# DA14682 register map
Vendor: Dialog; Series: DA14682; File version: 1.2
CPU: CM0 r1p0, little endian, MPU, FPU, 3 interrupt priority bits
Registers are 16-bit, read-write, reset 0x0 unless marked. A register's access mark holds for its fields unless they carry their own. Offsets are from the block's base; [hi:lo] are bit positions; <NAME> marks a mode.

## ANAMISC — ANAMISC registers
Base 0x50001B00
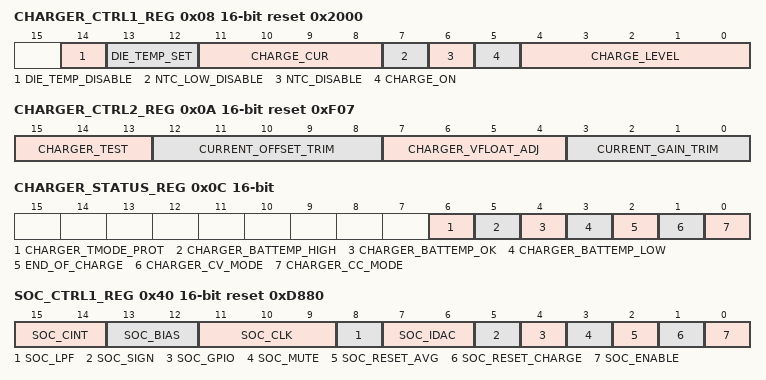
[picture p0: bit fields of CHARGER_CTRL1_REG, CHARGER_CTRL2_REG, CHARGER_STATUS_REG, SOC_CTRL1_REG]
0x08 CHARGER_CTRL1_REG reset 0x2000 — Charger control register 1
  [14] DIE_TEMP_DISABLE — 0: Die temperature protection enabled: charger will be disabled when die temp exceeds value set in DIE_TEMP_SET 1: Die temperature protection disabled: testmode, use only in agreement with Dialog
  [13:12] DIE_TEMP_SET — Die temperature protection level. Charging will be automatically disabled if set level is exceeded and resumed when temperature has dropped few degrees below set level. 00: 0oC (do not use, for test only) 01: 50oC (do not use, for test only) 10: 80oC (default) 11: 100oC
  [11:8] CHARGE_CUR — Constant Current levels (typical values) 0000: 5 mA 0001: 10 mA 0010: 30 mA 0011: 45 mA 0100: 60 mA 0101: 90 mA 0110: 120 mA 0111: 150 mA 1000: 180 mA 1001: 210 mA 1010: 270 mA 1011: 300 mA 1100: 350 mA 1101: 400 mA
  [7] NTC_LOW_DISABLE — 0: Normal operation: voltage level higher than 7/8 VDD_USB will disable the charger 1: NTC low temp limit disabled: use if trickle charging below the minimum temperature is required
  [6] NTC_DISABLE — 0: Charger NTC protection enabled 1: Charger NTC protection disable
  [5] CHARGE_ON — 0: Charger in powerdown 1: Charger enabled
  [4:0] CHARGE_LEVEL — Constant Voltage Levels 00000: 3.00V (reset) 00001: 3.40V (e.g. 2xNiMH) 00010: 3.50V 00011: 3.60V (e.g. Li-phosphate) 00100: 3.74V 00101: 3.86V 00110: 4.00V 00111: 4.05V 01000: 4.10V 01001: 4.15V 01010: 4.20V (e.g. Li-Co, Li-Mn, NMC) 01011: 4.25V 01100: 4.30V 01101: 4.35V 01110: 4.40V 01111: 4.50V 10000: 4.60V 10001: 4.90V e.g. 3xNiMH 10010: 5.00V
0x0A CHARGER_CTRL2_REG reset 0xF07 — Charger control register 2
  [15:13] CHARGER_TEST — Signals are mapped on SPDIF pin. Also set ANA_TEST_REG[ANA_TESTBUS_TO_ADCPIN] = 1 000: normal mode (no test selected) 001: Vptat (temperature sensor) [1.4V max] 010: Vbat_sense after divider [1.2V] 011: Current loop output [0 to vsupply] 100: Voltage loop output [0 to vsupply] 101: Imeas or Iref/10 110: Icharge reduced by 26.6 111: reserved
  [12:8] CURRENT_OFFSET_TRIM — do not change, for test purpose only
  [7:4] CHARGER_VFLOAT_ADJ — Independent adjustment for the charge level. Adjust range is +/- 1.8 percent. The 4 bits adjustment is in two's complement.
  [3:0] CURRENT_GAIN_TRIM — do not change, for test purpose only
0x0C CHARGER_STATUS_REG — Charger status and trimming register
  [6] CHARGER_TMODE_PROT ro — 0: Dietemp below DIE_TEMP_SET level. Normal operation 1: Dietemp above DIE_TEMP_SET level. Charging is disabled
  [5] CHARGER_BATTEMP_HIGH ro — 0: Battery pack temperature 'ok' or 'too low' (voltage level on NTC pin above 1/2 VDD_USB) 1: Battery pack temperature 'too high' (voltage level on NTC pin below 1/2 VDD_USB)
  [4] CHARGER_BATTEMP_OK ro — 0: Battery pack temperature 'too low' or 'too high' (voltage level on NTC pin below 1/2 or above 7/8 VDD_USB) 1: Battery pack temperature 'ok' (voltage level on NTC pin between 1/2 and 7/8 VDD_USB)
  [3] CHARGER_BATTEMP_LOW ro — 0: Battery pack temperature 'ok' or 'too high' (voltage level on NTC pin below 7/8 VDD_USB) 1: Battery pack temperature 'too low' (voltage level on NTC pin above than 7/8 VDD_USB)
  [2] END_OF_CHARGE ro — 0: Actual charge current is between 10...100 percent of set CHARGE_CUR (or CHARGE_ON=0) 1: Actual charge current <10 percent of set CHARGE_CUR
  [1] CHARGER_CV_MODE ro — 0: voltage loop not in regulation (or charger is off) 1: constant voltage mode active, voltage loop in regulation.
  [0] CHARGER_CC_MODE ro — 0: current loop not in regulation (or charger is off) 1: constant current mode active, current loop in regulation.
0x40 SOC_CTRL1_REG reset 0xD880 — Fuel Gauge Control register 1
  [15:14] SOC_CINT — Integrator capacitor scaler 0: Cint = 1 pF 1: Cint = 2 pF 2: Cint = 4 pF 3: Cint = 8 pF (=default)
  [13:12] SOC_BIAS — Current DAC scaler 0: Ibias = 2 uA 1: Ibias = 1 uA (=default) 2: Ibias = 0.5 uA 3: Ibias = 0.25 uA
  [11:9] SOC_CLK — SOC Sample frequency 0: automatic mode (tbd) 1: fs = 18 kHz 2: fs = 36 kHz 3: fs = 72 kHz 4: fs = 144 kHz (=default) 5: fs = 288 kHz 6: fs = 576 kHz 7: fs = 1152 kHz
  [8] SOC_LPF — 0: low-pass filter at integrator inputs disabled 1: Enables a low-pass filter at the integrator inputs
  [7:6] SOC_IDAC — Scales the current DAC (Ibias: default=1uA) 0: Idac=0.25*Ibias 1: Idac=0.5*Ibias 2: Idac=Ibias (=default) 3: Idac=2*Ibias
  [5] SOC_SIGN — Defines the sign of the charge converter input and output to perform a chopper function to eliminate offset voltage (see also SOC_CHOP and 'sign' on output pin) 0: non-inverted inputs and outputs 1: inverted inputs and outputs
  [4] SOC_GPIO — Reserved (not yet implemented): switches the SOC-inputs to the GPIO pins
  [3] SOC_MUTE — 0: Normal operation 1: Connect the input voltage to 0V
  [2] SOC_RESET_AVG — 1: Reset the SOC_CHARGE_AVG_REG to the last value of SOC_CHARGE_CNTRx_REG
  [1] SOC_RESET_CHARGE — 1: Reset CHARGE_CNTR_REG
  [0] SOC_ENABLE — 0: SOC analog circuits off. CHARGE_CNTRx_REG can still be written for a manual update. See SOC_ADD2CH_REG 1: SOC analog circuits enabled
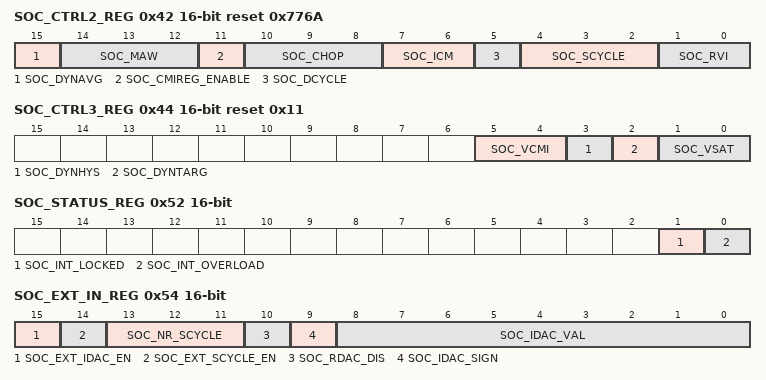
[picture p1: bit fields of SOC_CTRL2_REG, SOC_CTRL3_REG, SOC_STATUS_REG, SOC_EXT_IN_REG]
0x42 SOC_CTRL2_REG reset 0x776A — Fuel Gauge Control register 2
  [15] SOC_DYNAVG — if HIGH then 'weight' of Moving Average is forced to 1 if the converter detects significant input change (if dcharge > 4*delta_c, or high_limit, or low_limit)
  [14:12] SOC_MAW — Moving Average Weight factor charge_avg(n) = (weight*charge_avg(n-1) + charge(n) ) / (weight+1) where:weight = 2^(soc_maw)
  [11] SOC_CMIREG_ENABLE
  [10:8] SOC_CHOP — Chopping control 0: 'external' chopping control with 'soc_sign'-input 1: chop each 2^1*scycle fs-periods 2: chop each 2^2*scycle fs-periods .. 7: chop each 2^7*scycle fs-periods.
  [7:6] SOC_ICM — adds a common-mode current to Idac to increase the common-mode input-level of the integrator. The common-mode input level is equal to (Idac+Icm)*Rvi; 0: Icm=0; 1: Icm=1*Ibias (=default); 2: Icm=2*Ibias; 3: Icm=4*Ibias
  [5] SOC_DCYCLE — Cycle the current divider segments of Idac 0: no cycling 1: cycle each scycle fs-periods
  [4:2] SOC_SCYCLE — Cycle current segments (8 segments) of Idac 0: no cycling 1: cycle each fs-period 2: cycle each 2 fs-periods .. 7: cycle each 7 fs-periods
  [1:0] SOC_RVI — Voltage-to-current resistor scaler 0: Rvi = 25 k 1: Rvi = 50 k 2: Rvi = 100 k (= default) 3: Rvi = 200 k
0x44 SOC_CTRL3_REG reset 0x11 — Fuel Gauge Control register 3
  [5:4] SOC_VCMI — Common Input Voltage target of regulator (see SOC_CMIREG_ENABLE) 0: 50 mV 1: 100 mV 2: 150 mV 3: 200 mV
  [3] SOC_DYNHYS — Reserved. (To be implemented) Hysteresis of the comparator which detects if the integrator voltage is rising or falling
  [2] SOC_DYNTARG — Reserved. (To be implemented) 0: Vint_target = 0V 1: Vint_target tracks the 2 MSB's of the charge register)
  [1:0] SOC_VSAT — Trigger level of the high-limit and low-limit comparators. 0: low_limit = -50mV; high_limit = +50mV 1: low_limit = -100mV; high_limit = +100mV (=default) 2: low_limit = -200mV; high_limit = +200mV 3: low_limit = -400mV; high_limit = +400mV
0x46 SOC_ADD2CH_REG — Fuel Gauge manually add extra charge to SOC_CHARGE_CNTRx_REG
  [15:0] SOC_ADD2CH — Extra charge to be added to the SOC_CHARGE_CNTRx_REG per sample period (9-bit + sign + 6 fractional bits
0x48 SOC_CHARGE_CNTR1_REG — Fuel Gauge Charge counter bits 15-0
  [15:0] CHARGE_CNT1 ro — Sum of the charge-values per sampling period; (bits15:0) The absolute full-scale charge value is 6-bits, At full scale charge current it takes 2^26 sampling periods until overflow of the charge_cnt register after a reset_charge event. At fs=144kHz (=default) this will happen after 33 hours At fs=1.152MHz After 10 hours
0x4A SOC_CHARGE_CNTR2_REG — Fuel Gauge Charge counter bits 31-16
  [15:0] CHARGE_CNT2 ro — Sum of the charge-values per sampling period; (bits23:16)
0x4C SOC_CHARGE_CNTR3_REG — Fuel Gauge Charge counter bits 39-32
  [7:0] CHARGE_CNT3 ro — Sum of the charge-values per sampling period; (bits39:24)
0x50 SOC_CHARGE_AVG_REG — Fuel Gauge Average charge counter
  [15:0] CHARGE_AVG ro — Average of 'charge' current (9-bit + sign and 6 fractional bits
0x52 SOC_STATUS_REG — Fuel Gauge Status register
  [1] SOC_INT_LOCKED ro — 0: Normal Operation 1: Integrator is pushed over high or low limit. Returns to '0' if the converter runs for more than 2 sequential sampling periods in a 'safe' region (dcharge < 2*delta_c)
  [0] SOC_INT_OVERLOAD ro — 0: Normal Operation 1: Integrator exceeds high or low limit with full-scale IDAC (charge) for more than 3 sequential sampling periods
0x54 SOC_EXT_IN_REG — Fuel Gauge input test register
  [15] SOC_EXT_IDAC_EN — 1: Enable 'external' control of Idac
  [14] SOC_EXT_SCYCLE_EN — 1: Enable 'external' control of scycle
  [13:11] SOC_NR_SCYCLE — Number of the scycle
  [10] SOC_RDAC_DIS — 0: Disables the resistor divider DAC. The Idac has 6-bits (plus sign) 1: Enables the resistor divider DAC. The Idac has 9-bits (plus sign)
  [9] SOC_IDAC_SIGN — 0: SOC_IDAC_VAL is positive 1: SOC_IDAC_VAL is negative
  [8:0] SOC_IDAC_VAL — Controls the current for the DAC. 0: 0/512*SOC_IDAC N: N/512*SOC_IDAC
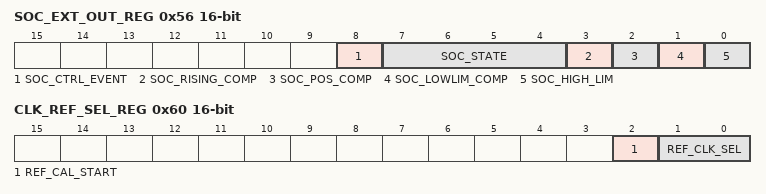
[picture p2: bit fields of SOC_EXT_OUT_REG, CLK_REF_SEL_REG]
0x56 SOC_EXT_OUT_REG — Fuel Gauge output test register
  [8] SOC_CTRL_EVENT ro — Controller event
  [7:4] SOC_STATE ro — Controller state
  [3] SOC_RISING_COMP ro — Rising comparator output
  [2] SOC_POS_COMP ro — Positive comparator output
  [1] SOC_LOWLIM_COMP ro — Low_limit comparator output
  [0] SOC_HIGH_LIM ro — High_limit comparator output
0x60 CLK_REF_SEL_REG — Select clock for oscillator calibration
  [2] REF_CAL_START — Writing a '1' starts a calibration. This bit is cleared when calibration is finished, and CLK_REF_VAL is ready.
  [1:0] REF_CLK_SEL — Select clock input for calibration: 0x0 : RC32K oscillator 0x1 : RC16M oscillator 0x2 : XTAL32K oscillator 0x3 : RCX oscillator
0x62 CLK_REF_CNT_REG — Count value for oscillator calibration
  [15:0] REF_CNT_VAL — Indicates the calibration time, with a decrement counter to 1.
0x64 CLK_REF_VAL_L_REG — DIVN reference cycles, lower 16 bits
  [15:0] XTAL_CNT_VAL ro — Returns the lower 16 bits of DIVN clock cycles counted during the calibration time, defined with REF_CNT_VAL
0x66 CLK_REF_VAL_H_REG — DIVN reference cycles, upper 16 bits
  [15:0] XTAL_CNT_VAL ro — Returns the upper 16 bits of DIVN clock cycles counted during the calibration time, defined with REF_CNT_VAL

## Notices in the file
Copyright (C) 2018 Dialog Semiconductor.
This computer program includes Confidential, Proprietary Information
of Dialog Semiconductor. All Rights Reserved.
